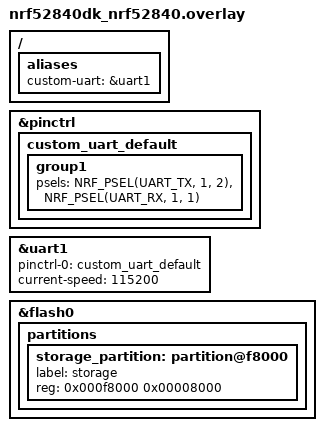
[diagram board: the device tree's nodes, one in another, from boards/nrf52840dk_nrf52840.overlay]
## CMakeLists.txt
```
#
# Copyright (c) 2020 Nordic Semiconductor ASA
#
# SPDX-License-Identifier: LicenseRef-Nordic-5-Clause
#
cmake_minimum_required(VERSION 3.20.0)

find_package(Zephyr REQUIRED HINTS $ENV{ZEPHYR_BASE})

project(test_storage)

target_sources(app PRIVATE src/main.c)

target_sources_ifdef(CONFIG_FLASH app PRIVATE src/storage_usr.c)
target_include_directories_ifdef(CONFIG_FLASH app PRIVATE src)
```

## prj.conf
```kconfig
#
# Copyright (c) 2020 Nordic Semiconductor
#
# SPDX-License-Identifier: LicenseRef-Nordic-5-Clause
#

# CONFIG_PRINTK=y
# CONFIG_LOG=y
# CONFIG_ASSERT=n

# uart enable
CONFIG_SERIAL=y
CONFIG_UART_ASYNC_API=y

CONFIG_GPIO=y

CONFIG_FLASH=y
CONFIG_FLASH_PAGE_LAYOUT=y
CONFIG_FLASH_MAP=y
CONFIG_NVS=y
```

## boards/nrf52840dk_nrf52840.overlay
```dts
/* Copyright (c) 2020 Nordic Semiconductor ASA
 *
 * SPDX-License-Identifier: LicenseRef-Nordic-5-Clause
 */

/ {
	aliases {
		custom-uart = &uart1;
	};
};

&pinctrl {
	custom_uart_default: custom_uart_default {
		group1 {
			psels = <NRF_PSEL(UART_TX, 1, 2)>,
				<NRF_PSEL(UART_RX, 1, 1)>;
		};
	};
};

&uart1 {
    pinctrl-0 = <&custom_uart_default>;
    current-speed = <115200>;
    status = "okay";
};

&flash0 {
    partitions {
        storage_partition: partition@f8000 {
            label = "storage";
            reg = <0x000f8000 0x00008000>; // 示例：从 992KB 开始，大小 32KB
        };
    };
};
```

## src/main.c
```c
#include <zephyr/device.h>
#include <zephyr/drivers/uart.h>
#include <zephyr/kernel.h>

#include "storage_usr.h"

#define CUSTOM_UART_NODE DT_ALIAS(custom_uart)
const struct device* custom_uart_dev = DEVICE_DT_GET(CUSTOM_UART_NODE);

int main(void)
{
    uint8_t tx_buf[100] = {0};
    uint8_t rx_buf[100] = {0};

#if (CONFIG_FLASH)
    init_storage();
#endif

    if (!device_is_ready(custom_uart_dev)) {
        return;
    }

#if (CONFIG_FLASH)
    load_parameter(tx_buf, 8);
#endif
    uart_tx(custom_uart_dev, tx_buf, 8, 0);

    for (;;) {
        uart_rx_enable(custom_uart_dev, rx_buf, 8, 0);
        if (0xaa == rx_buf[0] && 0x55 == rx_buf[1]) {
#if (CONFIG_FLASH)
            save_parameter(rx_buf, 8);
#endif
        }
    }

    return 0;
}
```

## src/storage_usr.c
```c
#include <zephyr/drivers/flash.h>
#include <zephyr/fs/nvs.h>
#include <zephyr/storage/flash_map.h>

static struct nvs_fs fs;
#define FS_SECTOR_COUNT (3)
#define CONFIG_ID (1)

void save_parameter(uint8_t* buf, uint16_t len) { nvs_write(&fs, CONFIG_ID, buf, len); }

void load_parameter(uint8_t* buf, uint16_t len) { ssize_t rc = nvs_read(&fs, CONFIG_ID, buf, len); }

void init_storage(void)
{
    int rc;
    struct flash_pages_info info;

    // 获取 storage 分区信息
    fs.flash_device = FLASH_AREA_DEVICE(storage_partition);
    fs.offset = FLASH_AREA_OFFSET(storage_partition);

    rc = flash_get_page_info_by_offs(fs.flash_device, fs.offset, &info);
    fs.sector_size = info.size;
    fs.sector_count = FS_SECTOR_COUNT;  // 根据分区大小设置扇区数量

    rc = nvs_mount(&fs);
}
```

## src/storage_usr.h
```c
#ifndef __STORAGE_USR_H__
#define __STORAGE_USR_H__

#include <stdint.h>

void save_parameter(uint8_t* buf, uint16_t len);
void load_parameter(uint8_t* buf, uint16_t len);
void init_storage(void);

#endif
```
